# STM32WBA23 register map
File version: 1.0
CPU: CM33 r0p1, little endian, MPU, FPU, 4 interrupt priority bits
Registers are 32-bit, read-write, reset 0x0 unless marked. A register's access mark holds for its fields unless they carry their own. Offsets are from the block's base; [hi:lo] are bit positions; {n}, {i} and the like mark numbered series; <NAME> marks a mode.

## PWR — PWR address block description
Base 0x46020800
Same registers: SEC_PWR 0x56020800
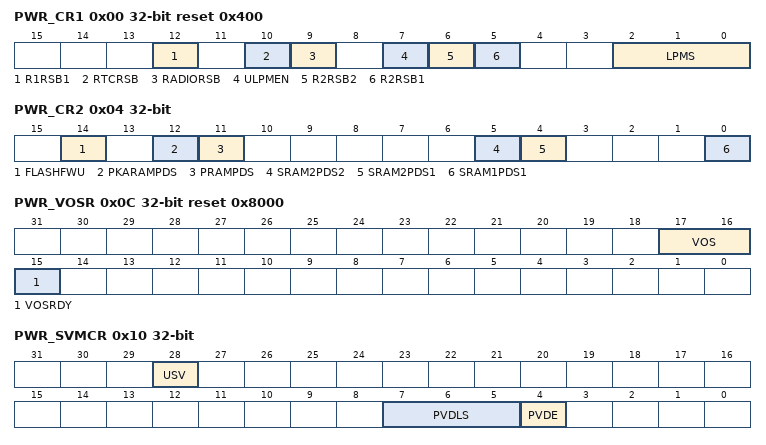
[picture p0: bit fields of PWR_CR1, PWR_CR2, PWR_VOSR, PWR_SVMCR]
0x00 PWR_CR1 reset 0x400 — PWR control register 1
  [12] R1RSB1 — SRAM1 page 1, 64 KB retention in Standby mode
    0=SRAM1 page 1 content not retained in Standby mode; 1=SRAM1 page 1 content retained in Standby mode
  [10] RTCRSB — RTC and TAMP retention in Standby mode.
    0=RTC and TAMP content not retained in Standby mode (If any other SRAM retention in Standby mode bit (RxRSBy) is enabled, RTC and TAMP are also functionality and retained in Standby mode); 1=RTC and TAMP functionality retained in Standby mode
  [9] RADIORSB — 2.
    0=2; 1=2
  [7] ULPMEN — BOR0 ultra-low-power mode.
    0=BOR0 operating in continuous (normal) mode in all operating modes; 1=BOR0 operating in discontinuous (ultra-low-power) mode in Stop 1, 2, 3, and Standby modes
  [6] R2RSB2 — SRAM2 page 2, 24 KB retention in Standby mode
    0=SRAM2 page 2 content not retained in Standby mode; 1=SRAM2 page 2 content retained in Standby mode
  [5] R2RSB1 — SRAM2 page 1, 8 KB retention in Standby mode
    0=SRAM2 page 1 content not retained in Standby mode; 1=SRAM2 page 1 content retained in Standby mode
  [2:0] LPMS — Low-power mode selection
    {v}=Stop {v} mode (v=0..3)
0x04 PWR_CR2 — PWR control register 2
  [14] FLASHFWU — Flash memory fast wakeup from Stop modes (Stop 0, 1)
    0=Flash memory enters low-power mode in Stop 0 and Stop 1 modes (lower-power consumption); 1=Flash memory remains in normal mode in Stop 0 and Stop 1 modes (faster wakeup time)
  [12] PKARAMPDS — PKA SRAM power-down in Stop 0 and Stop 1 modes
    0=PKA SRAM content retained in Stop modes; 1=PKA SRAM content lost in Stop modes
  [11] PRAMPDS — Peripheral USB power-down in Stop modes
    0=Peripheral USNB_FS SRAM content retained in Stop modes; 1=Peripheral USB SRAM content lost in Stop modes
  [5] SRAM2PDS2 — SRAM2 page 2, 24 KB power-down in Stop modes
    0=SRAM2 page 2 content retained in Stop modes; 1=SRAM2 page 2 content lost in Stop modes
  [4] SRAM2PDS1 — SRAM2 page 1, 8 KB power-down in Stop modes
    0=SRAM2 page 1 content retained in Stop modes; 1=SRAM2 page 1 content lost in Stop modes
  [0] SRAM1PDS1 — SRAM1 page 1, 64 KB power-down in Stop modes
    0=SRAM1 page 1 content retained in Stop modes; 1=SRAM1 page 1 content lost in Stop modes
0x0C PWR_VOSR reset 0x8000 — PWR voltage scaling register
  [17:16] VOS — Voltage scaling range selection
    0=Range 2 (lowest power); 1=Range 1 (highest frequency); 2=Range 1
  [15] VOSRDY ro — Ready bit for V<sub>CORE</sub> voltage scaling output selection
    0=Not ready, voltage level less than VOS selected level; 1=Ready, voltage level greater or equal VOS selected level
0x10 PWR_SVMCR — PWR supply voltage monitoring control register
  [28] USV — VDDUSB supply valid
    0=VDDUSB not supplied, electrical and logical isolation enabled; 1=VDDUSB supply present, electrical and logical isolation disabled
  [7:5] PVDLS — Programmable voltage detector level selection
    {v}=V<sub>PVD{v}</sub> ~ 2 (v=0..6)
  [4] PVDE — Programmable voltage detector enable
    0=Programmable voltage detector disabled; 1=Programmable voltage detector enabled
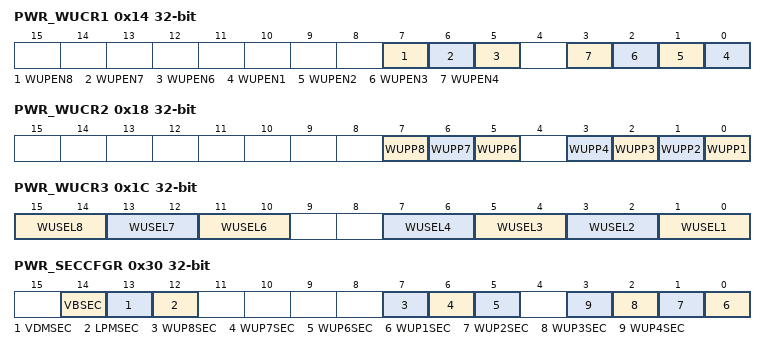
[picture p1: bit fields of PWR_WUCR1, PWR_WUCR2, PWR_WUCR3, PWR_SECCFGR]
0x14 PWR_WUCR1 — PWR wakeup control register 1
  [7] WUPEN8 — Wakeup and interrupt pin WKUP8 enable
    0=Wakeup and interrupt pin WKUP8 disabled; 1=Wakeup and interrupt pin WKUP8 enabled
  [6] WUPEN7 — Wakeup and interrupt pin WKUP7 enable
    0=Wakeup and interrupt pin WKUP7 disabled; 1=Wakeup and interrupt pin WKUP7 enabled
  [5] WUPEN6 — Wakeup and interrupt pin WKUP6 enable
    0=Wakeup and interrupt pin WKUP6 disabled; 1=Wakeup and interrupt pin WKUP6 enabled
  [n-1] WUPEN{n} (n=1..4) — Wakeup and interrupt pin WKUP{n} enable
    0=Wakeup and interrupt pin WKUP{n} disabled; 1=Wakeup and interrupt pin WKUP{n} enabled
0x18 PWR_WUCR2 — PWR wakeup control register 2
  [all] fields
    0=Detection on high level (rising edge); 1=Detection on low level (falling edge)
  [7] WUPP8 — Wakeup pin WKUP8 polarity
  [6] WUPP7 — Wakeup pin WKUP7 polarity
  [5] WUPP6 — Wakeup pin WKUP6 polarity
  [3] WUPP4 — Wakeup pin WKUP4 polarity
  [2] WUPP3 — Wakeup pin WKUP3 polarity
  [1] WUPP2 — Wakeup pin WKUP2 polarity
  [0] WUPP1 — Wakeup pin WKUP1 polarity.
0x1C PWR_WUCR3 — PWR wakeup control register 3
  [15:14] WUSEL8 — Wakeup and interrupt pin WKUP8 selection
    1=WKUP8_1; 2=WKUP8_2; 3=WKUP8_3 (internal source, does not generate a WKUP interrupt)
  [13:12] WUSEL7 — Wakeup and interrupt pin WKUP7 selection
    1=WKUP7_1; 3=WKUP7_3 (internal source, does not generate a WKUP interrupt)
  [11:10] WUSEL6 — Wakeup and interrupt pin WKUP6 selection
    0=WKUP6_0; 1=WKUP6_1; 3=WKUP6_3 (internal source, does not generate a WKUP interrupt)
  [7:6] WUSEL4 — Wakeup and interrupt pin WKUP4 selection
    0=WKUP4_0
  [5:4] WUSEL3 — Wakeup and interrupt pin WKUP3 selection
    1=WKUP3_1; 2=WKUP3_2
  [3:2] WUSEL2 — Wakeup and interrupt pin WKUP2 selection
    1=WKUP2_1
  [1:0] WUSEL1 — Wakeup and interrupt pin WKUP1 selection
    0=WKUP1_0; 1=WKUP1_1
0x28 PWR_DBPR — PWR disable Backup domain register
  [0] DBP — Disable Backup domain write protection
    0=Write access to Backup domain disabled; 1=Write access to Backup domain enabled
0x30 PWR_SECCFGR — PWR security configuration register
  [14] VBSEC — Backup domain secure protection
    0=PWR_DBPR can be read and written with secure or nonsecure access; 1=PWR_DBPR can be read and written only with secure access
  [13] VDMSEC — Voltage detection secure protection
    0=PWR_SVMCR and PWR_CR3 can be read and written with secure or nonsecure access; 1=PWR_SVMCR and PWR_CR3 can be read and written only with secure access
  [12] LPMSEC — Low-power modes secure protection
    0=PWR_CR1, PWR_CR2 and CSSF in the PWR_SR can be read and written with secure or nonsecure access; 1=PWR_CR1, PWR_CR2, and CSSF in the PWR_SR can be read and written only with secure access
  [7] WUP8SEC — WUP8 secure protection
    0=Bits related to the WKUP8 pin in PWR_WUCR1, PWR_WUCR2, PWR_WUCR3 and PWR_WUSCR can be read and written with secure or nonsecure access; 1=Bits related to the WKUP8 pin in PWR_WUCR1, PWR_WUCR2, PWR_WUCR3 and PWR_WUSCR can be read and written only with secure access
  [6] WUP7SEC — WUP7 secure protection
    0=Bits related to the WKUP7 pin in PWR_WUCR1, PWR_WUCR2, PWR_WUCR3 and PWR_WUSCR can be read and written with secure or nonsecure access; 1=Bits related to the WKUP7 pin in PWR_WUCR1, PWR_WUCR2, PWR_WUCR3 and PWR_WUSCR can be read and written only with secure access
  [5] WUP6SEC — WUP6 secure protection
    0=Bits related to the WKUP6 pin in PWR_WUCR1, PWR_WUCR2, PWR_WUCR3 and PWR_WUSCR can be read and written with secure or nonsecure access; 1=Bits related to the WKUP6 pin in PWR_WUCR1, PWR_WUCR2, PWR_WUCR3 and PWR_WUSCR can be read and written only with secure access
  [n-1] WUP{n}SEC (n=1..4) — WUP{n} secure protection
    0=Bits related to the WKUP{n} pin in PWR_WUCR1, PWR_WUCR2, PWR_WUCR3 and PWR_WUSCR can be read and written with secure or nonsecure access; 1=Bits related to the WKUP{n} pin in PWR_WUCR1, PWR_WUCR2, PWR_WUCR3 and PWR_WUSCR can be read and written only with secure access
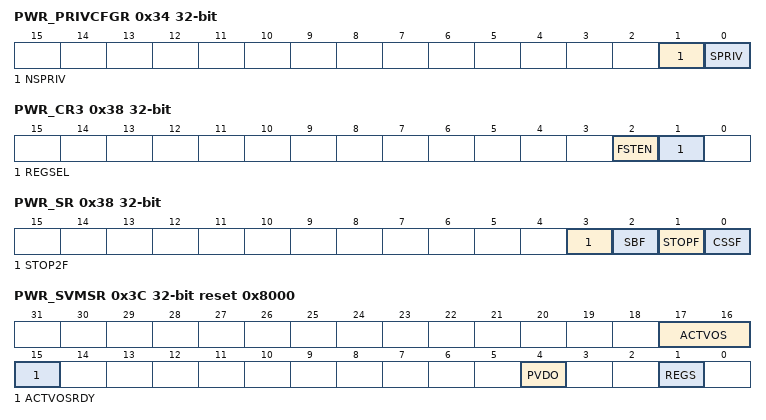
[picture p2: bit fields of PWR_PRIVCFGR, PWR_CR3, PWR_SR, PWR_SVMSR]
0x34 PWR_PRIVCFGR — PWR privilege control register
  [1] NSPRIV — PWR nonsecure functions privilege configuration
    0=Read and write to PWR nonsecure functions can be done by privileged or unprivileged access; 1=Read and write to PWR nonsecure functions can be done by privileged access only
  [0] SPRIV — PWR secure functions privilege configuration
    0=Read and write to PWR secure functions can be done by privileged or unprivileged access; 1=Read and write to PWR secure functions can be done by privileged access only
0x38 PWR_CR3 — PWR control register 3
  [2] FSTEN — Fast soft start
    0=LDO/SMPS fast startup disabled (limited inrush current after system reset and wakeup from Standby modes); 1=LDO/SMPS fast startup enabled
  [1] REGSEL — Regulator selection
    0=LDO selected; 1=SMPS selected
0x38 PWR_SR (alternate view of PWR_CR3) — PWR status register
  [3] STOP2F ro — Stop 2 and Stop 3 mode peripherals power down flag
    0=The device did not enter Stop 2 or Stop 3 mode; 1=The device entered Stop 2 or Stop 3 mode
  [2] SBF ro — Standby flag
    0=The device did not enter Standby mode; 1=The device entered Standby mode
  [1] STOPF ro — Stop flag
    0=The device did not enter any Stop mode; 1=The device entered a Stop mode
  [0] CSSF wo — Clear Stop and Standby flags
0x3C PWR_SVMSR ro reset 0x8000 — PWR supply voltage monitoring status register
  [17:16] ACTVOS — Voltage scaling range currently applied to V<sub>CORE</sub>
    0=Range 2 (lowest power); 1=Range 1 (highest frequency); 2=Range 1 (highest frequency, lower power)
  [15] ACTVOSRDY — Voltage level ready for currently used VOS
    0=V<sub>CORE</sub> is above or below the current voltage scaling provided by ACTVOS; 1=V<sub>CORE </sub>is equal to the current voltage scaling provided by ACTVOS
  [4] PVDO — Programmable voltage detector output
    0=V<sub>DD</sub> is equal or above the PVD threshold selected by PVDLS[2:0]; 1=V<sub>DD </sub>is below the PVD threshold selected by PVDLS[2:0]
  [1] REGS — Regulator selection
    0=LDO selected; 1=SMPS selected
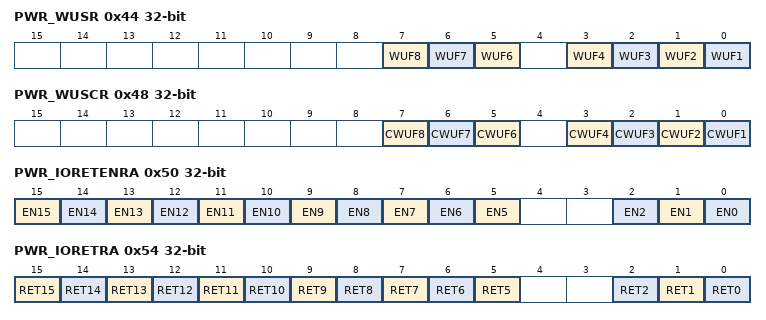
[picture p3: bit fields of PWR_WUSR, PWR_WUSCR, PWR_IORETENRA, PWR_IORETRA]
0x44 PWR_WUSR ro — PWR wakeup status register
  [7] WUF8 — Wakeup and interrupt pending flag 8
  [6] WUF7 — Wakeup and interrupt pending flag 7
  [5] WUF6 — Wakeup and interrupt pending flag 6
  [n-1] WUF{n} (n=1..4) — Wakeup and interrupt pending flag {n}
0x48 PWR_WUSCR wo — PWR wakeup status clear register
  [7] CWUF8 — Clear wakeup flag 8
  [6] CWUF7 — Clear wakeup flag 7
  [5] CWUF6 — Clear wakeup flag 6
  [n-1] CWUF{n} (n=1..4) — Clear wakeup flag {n}
0x50 PWR_IORETENRA — PWR port A Standby IO retention enable register
  [n] EN{n} (n=5..15) — Port A Standby GPIO pin y (y = 15 to 5) retention enable
    0=PAy Standby GPIO retention feature disabled; 1=PAy Standby GPIO retention feature enabled
  [2] EN2 — Port A Standby GPIO pin y (y = 2 to 0) retention enable
  [1] EN1 — Port A Standby GPIO pin y (y = 2 to 0) retention enable
  [0] EN0 — Port A Standby GPIO pin y (y = 2 to 0) retention enable
0x54 PWR_IORETRA — PWR port A Standby IO retention status register
  [n] RET{n} (n=5..15) — Port A Standby GPIO pin y (y = 15 to 5) retention enable
    1=Set by hardware when Standby GPIO PAy is enabled in PWR_IORETENRA and Standby mode is entered; 0=Cleared by software, writing 0
  [2] RET2 — Port A Standby GPIO pin y (y = 2 to 0) retention enable
  [1] RET1 — Port A Standby GPIO pin y (y = 2 to 0) retention enable
  [0] RET0 — Port A Standby GPIO pin y (y = 2 to 0) retention enable
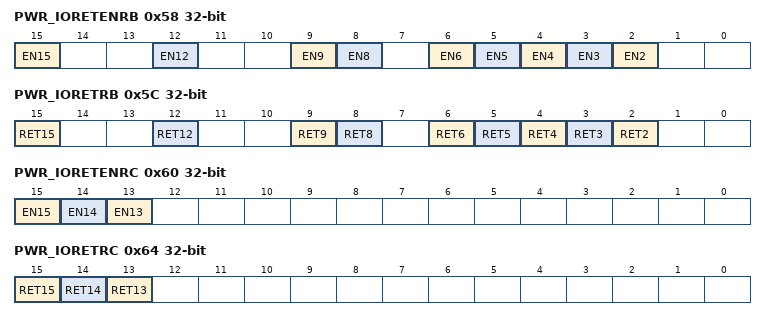
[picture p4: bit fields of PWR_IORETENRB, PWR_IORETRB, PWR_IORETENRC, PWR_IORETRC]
0x58 PWR_IORETENRB — PWR port B Standby IO retention enable register
  [15] EN15
  [12] EN12
  [9] EN9 — Port B Standby GPIO pin y (y = 9 to 8) retention enable
  [8] EN8 — Port B Standby GPIO pin y (y = 9 to 8) retention enable
  [n] EN{n} (n=2..6) — Port B Standby GPIO pin y (y = 6 to 2) retention enable
0x5C PWR_IORETRB — PWR port B Standby IO retention status register
  [15] RET15
  [12] RET12
  [9] RET9 — Port B Standby GPIO pin y (y = 9 to 8) retention enable
  [8] RET8 — Port B Standby GPIO pin y (y = 9 to 8) retention enable
  [n] RET{n} (n=2..6) — Port B Standby GPIO pin y (y = 6 to 2) retention enable
0x60 PWR_IORETENRC — PWR port C Standby IO retention enable register
  [all] fields
    0=PCy Standby GPIO retention feature disabled; 1=PCy Standby GPIO retention feature enabled
  [15] EN15 — Port C Standby GPIO pin y (y = 15 to 13) retention enable
  [14] EN14 — Port C Standby GPIO pin y (y = 15 to 13) retention enable
  [13] EN13 — Port C Standby GPIO pin y (y = 15 to 13) retention enable
0x64 PWR_IORETRC — PWR port C Standby IO retention status register
  [all] fields
    1=Set by hardware when Standby GPIO PCy is enabled in PWR_IORETENRC and Standby mode is entered; 0=Cleared by software, writing 0
  [15] RET15 — Port C Standby GPIO pin y (y = 15 to 13) retention enable
  [14] RET14 — Port C Standby GPIO pin y (y = 15 to 13) retention enable
  [13] RET13 — Port C Standby GPIO pin y (y = 15 to 13) retention enable
0x88 PWR_IORETENRH — PWR port H Standby IO retention enable register
  [3] EN3 — Port H Standby GPIO pin y (y = 3) retention enable
    0=PHy Standby GPIO retention feature disabled; 1=PHy Standby GPIO retention feature enabled
0x8C PWR_IORETRH — PWR port H Standby IO retention status register
  [3] RET3 — Port H Standby GPIO pin y (y = 3) retention enable
    1=Set by hardware when Standby GPIO PHy is enabled in PWR_IORETENRH and Standby mode is entered; 0=Cleared by software, writing 0
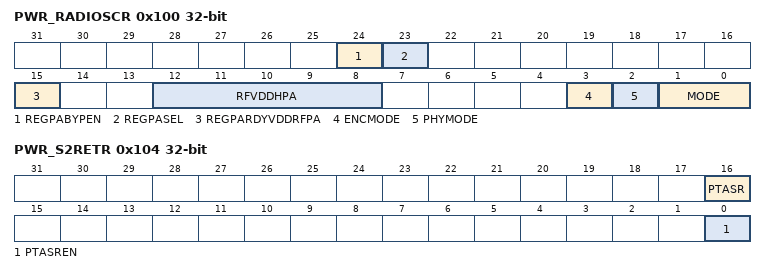
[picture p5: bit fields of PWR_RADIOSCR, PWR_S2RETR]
0x100 PWR_RADIOSCR — PWR 2.
  [24] REGPABYPEN — regulator REG_VDDHPA bypass enable.
    0=2; 1=2
  [23] REGPASEL — regulator REG_VDDHPA input supply selection.
    0=VDDRFPA pin selected as regulator REG_VDDHPA input supply; 1=regulator REG_VDDHPA input supply selection between VDDRFPA and VDD11 dependent on requested regulated output voltage
  [15] REGPARDYVDDRFPA ro — Ready bit for V<sub>DDHPA</sub> voltage level when selecting VDDRFPA input.
    0=Not ready, V<sub>DDHPA</sub> voltage level less than REGPAVOS selected supply level; 1=Ready, V<sub>DDHPA</sub> voltage level greater or equal REGPAVOS selected supply level
  [12:8] RFVDDHPA ro — 2.
  [3] ENCMODE ro — 2.
    0=2; 1=2
  [2] PHYMODE ro — 2.
    0=2; 1=2
  [1:0] MODE ro — 2.
    0=2; 1=2
0x104 PWR_S2RETR — PWR Stop 2 peripheral IOs retention register
  [16] PTASR — PTA interface output signals state retention in Stop 2 and 3 mode active.
    1=Set by hardware when Stop 2 and Stop 3 mode PTA retention is enabled in PTASREN and Stop 2 and Stop 3 mode is entered; 0=Cleared by software, writing 0
  [0] PTASREN — PTA output signals Stop 2 and Stop 3 mode retention enable
    0=PTA output signals Stop 2 and Stop 3 retention feature disabled; 1=PTA output signals Stop 2 and Stop 3 retention feature enabled
